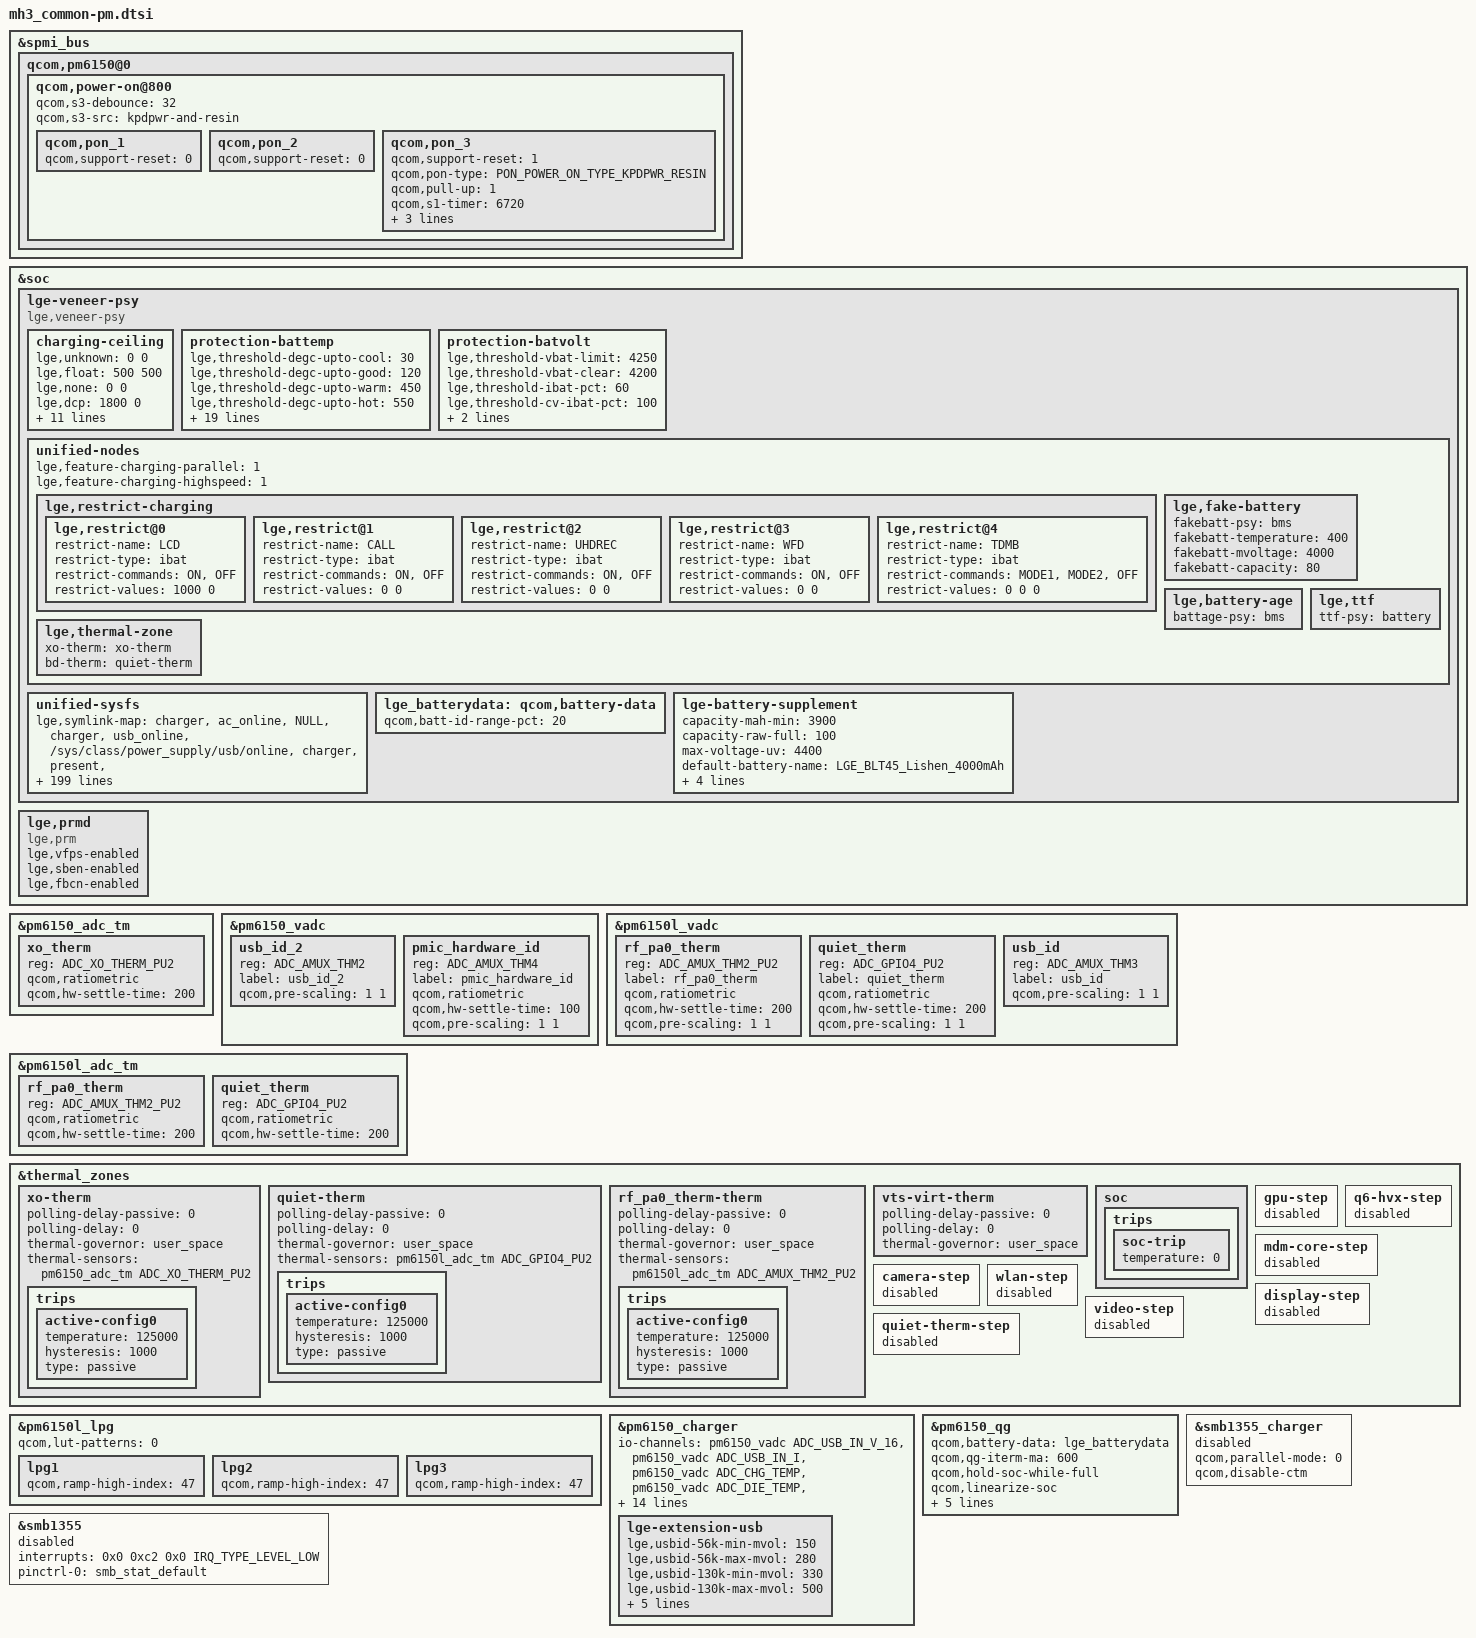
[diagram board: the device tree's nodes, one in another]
/*
 * Copyright (c) 2018, The Linux Foundation. All rights reserved.
 *
 * This program is free software; you can redistribute it and/or modify
 * it under the terms of the GNU General Public License version 2 and
 * only version 2 as published by the Free Software Foundation.
 *
 * This program is distributed in the hope that it will be useful,
 * but WITHOUT ANY WARRANTY; without even the implied warranty of
 * MERCHANTABILITY or FITNESS FOR A PARTICULAR PURPOSE.  See the
 * GNU General Public License for more details.
 */
#include <dt-bindings/input/qcom,qpnp-power-on.h>

&spmi_bus {
       qcom,pm6150@0 {
               qcom,power-on@800 {
                       qcom,s3-debounce = <32>;
                       qcom,s3-src = "kpdpwr-and-resin";

                       qcom,pon_1 {
                               /* KPD_PWR_N */
                               status = "ok";
                               qcom,support-reset = <0>;
                       };

                       qcom,pon_2 {
                               /* RESIN_N */
                               status = "ok";
                               qcom,support-reset = <0>;
                       };

                       qcom,pon_3 {
                               /* KPD_PWR_N AND RESIN_N */
                               status = "ok";
                               qcom,support-reset = <1>;
                               qcom,pon-type = <PON_POWER_ON_TYPE_KPDPWR_RESIN>;
                               qcom,pull-up = <1>;
                               qcom,s1-timer = <6720>;
                               qcom,s2-timer = <2000>;
                               qcom,s2-type = <PON_POWER_OFF_TYPE_DVDD_HARD_RESET>;
                       };
               };
       };
};

&soc {
    lge-veneer-psy {
        compatible = "lge,veneer-psy";
        status = "ok";

        charging-ceiling {
            /*             iusb ibat  : 0 means UNCEILING */
            lge,unknown = <   0    0>;
            lge,float   = < 500  500>;
            lge,none    = <   0    0>;

            lge,dcp     = <1800    0>;
            lge,10k     = <3000    0>;
            lge,22k     = <1500    0>;
            lge,qc2     = <1800    0>;
            lge,qc3     = <1800    0>;

            lge,usb2    = < 500    0>;
            lge,usb3    = < 900    0>;
            lge,cdp     = <1500 1500>;
            lge,pd      = <   0    0>;

            lge,56k     = <1500  500>;
            lge,130k    = <1500  500>;
            lge,910k    = <1500  500>;
        };

        protection-battemp {
            lge,threshold-degc-upto-cool = <30>;
            lge,threshold-degc-upto-good = <120>;
            lge,threshold-degc-upto-warm = <450>;
            lge,threshold-degc-upto-hot = <550>;
            lge,threshold-degc-downto-warm = <520>;
            lge,threshold-degc-downto-good = <430>;
            lge,threshold-degc-downto-cool = <100>;
            lge,threshold-degc-downto-cold = <0>;

            lge,period-ms-emergency = <10000>;
            lge,period-ms-warning   = <30000>;
            lge,period-ms-normal    = <60000>;

            // parameters for warning status cool and warm
            lge,cool-mv-alert   = <4000>;
            lge,cool-ma-alert   = <500>;    // fixed 500 mA
            lge,cool-ma-pct     = <30>;     // means 0.3C rate

            lge,warm-mv-float   = <4000>;
            lge,warm-ma-pct     = <30>;     // means 0.5C rate

            // parameters for battery protection at chilly status
            lge,chilly-status-support;
            lge,chilly-degc-lowerbound = <0>;
            lge,chilly-degc-upperbound = <150>;
            lge,chilly-mv-alert    = <4000>;
            lge,chilly-mv-bound     = <200>;
            lge,chilly-ma-alert    = <630>;
            lge,chilly-ma-pct      = <50>;  // means 0.5C rate under batvol 4V
        };

        protection-batvolt {
            lge,threshold-vbat-limit = <4250>;
            lge,threshold-vbat-clear = <4200>;
	    lge,threshold-ibat-pct = <60>;	// means 0.6C rate
	    lge,threshold-cv-ibat-pct = <100>;	// means 0.1C rate

            lge,step-ibat-ma = <100>;
            lge,step-poll-ms = <5000>;
        };

        unified-nodes {
            lge,feature-charging-parallel = <1>;
            lge,feature-charging-highspeed = <1>;

            lge,restrict-charging {
                // restrict-values 0 means UNCEILING

                lge,restrict@0 {
                    restrict-name = "LCD";
                    restrict-type = "ibat";
                    restrict-commands = "ON", "OFF";
                    restrict-values = <1000      0>;
                };
                lge,restrict@1 {
                    restrict-name = "CALL";
                    restrict-type = "ibat";
                    restrict-commands = "ON", "OFF";
                    restrict-values = < 0      0>;
                };
                lge,restrict@2 {
                    restrict-name = "UHDREC";
                    restrict-type = "ibat";
                    restrict-commands = "ON", "OFF";
                    restrict-values = < 0      0>;
                };
                lge,restrict@3 {
                    restrict-name = "WFD";
                    restrict-type = "ibat";
                    restrict-commands = "ON", "OFF";
                    restrict-values = < 0      0>;
                };
                lge,restrict@4 {
                    restrict-name = "TDMB";
                    restrict-type = "ibat";
                    restrict-commands = "MODE1", "MODE2", "OFF";
                    restrict-values = <    0      0      0>;
                };
            };

            lge,fake-battery {
                fakebatt-psy = "bms";       // What 'psy' does implement(or support) the fake battery?
                fakebatt-temperature = <400>;
                fakebatt-mvoltage = <4000>;
                fakebatt-capacity = <80>;
            };

            lge,battery-age {
                battage-psy = "bms";        // What 'psy' does implement(or support) the battery age?
            };

	    lge,thermal-zone {
	    	xo-therm = "xo-therm";
		bd-therm = "quiet-therm";
	    };

            lge,ttf {
                ttf-psy = "battery";	// What 'psy' does implement(or support) the time to full now?
            };
        };

        unified-sysfs {
            lge,symlink-map =
                /* group , user_node, kernel node */
                /* Charger */
                "charger",                     "ac_online", "NULL",
                "charger",                    "usb_online", "/sys/class/power_supply/usb/online",   /* TODO */
                "charger",                       "present", "/sys/class/power_supply/usb/present",
                "charger",                    "wlc_online", "/sys/class/power_supply/wireless/online",
                "charger",                          "type", "/sys/class/power_supply/usb/real_type",
		"charger",                   "usb_pd_type", "/sys/class/power_supply/usb/real_type",
                "charger",                      "time_out", "/sys/class/power_supply/battery/safety_timer_enabled",
                "charger",              "charging_enabled", "/sys/devices/platform/lge-unified-nodes/charging_enable",
                "charger",                  "ibat_current", "/sys/class/power_supply/battery/current_now",
                "charger",                  "ichg_current", "/sys/class/power_supply/usb/current_max",
                "charger",                  "iusb_control", "NULL",
                "charger",            "thermal_mitigation", "NULL",
                "charger",        "wlc_thermal_mitigation", "NULL",
                "charger",       "usb_parallel_chg_status", "NULL",
                "charger", "usb_parallel_charging_enabled", "/sys/class/power_supply/parallel/charging_enabled",
                "charger", "factory_parallel_charger_test", "/sys/devices/platform/lge-unified-nodes/support_fastpl",
                "charger",            "moisture_detection", "/sys/class/power_supply/usb/moisture_detected",
                "charger",           "restricted_charging", "/sys/devices/platform/lge-unified-nodes/charging_restriction",
                "charger",              "ibat_max_current", "/sys/class/power_supply/battery/constant_charge_current_max",
                "charger",                       "chgstep", "/sys/devices/platform/lge-unified-nodes/charging_step",
                "charger",               "connection_type", "NULL",
                "charger",                       "fastchg", "/sys/devices/platform/lge-unified-nodes/charger_highspeed",
                "charger",         "input_current_settled", "/sys/class/power_supply/usb/input_current_settled",
                "charger",             "input_current_max", "/sys/class/power_supply/usb/input_current_settled",
                "charger",            "store_demo_enabled", "NULL",
                "charger",     "wireless_charging_enabled", "NULL",
                "charger",                 "input_suspend", "/sys/class/power_supply/battery/input_suspend",
                "charger",                  "incompatible", "/sys/devices/platform/lge-unified-nodes/charger_incompatible",
                "charger",                    "hvdcp_fake", "/sys/devices/platform/lge-unified-nodes/fake_hvdcp",
                "charger",               "usb_current_max", "/sys/devices/platform/lge-unified-nodes/fake_sdpmax",
                "charger",               "fastchg_support", "/sys/devices/platform/lge-unified-nodes/support_fastchg",
                "charger",                    "usbid_type", "/sys/class/power_supply/usb/resistance_id",
                "charger",                 "ccd_batchg_en", "/sys/devices/platform/lge-unified-nodes/ccd_batchg_en",
                "charger",             "ccd_input_suspend", "/sys/devices/platform/lge-unified-nodes/ccd_input_suspend",
                "charger",                       "ccd_icl", "/sys/devices/platform/lge-unified-nodes/ccd_icl",
                "charger",                       "ccd_fcc", "/sys/devices/platform/lge-unified-nodes/ccd_fcc",
                "charger",                    "ccd_vfloat", "/sys/devices/platform/lge-unified-nodes/ccd_vfloat",
		"charger",                     "aicl_done", "/sys/devices/platform/lge-unified-nodes/aicl_done",
                /* ADC/MPP */
                "adc",              "thermal", "/sys/class/thermal/",
		"adc",             "xo_therm", "/sys/bus/iio/devices/iio:device0/in_temp_xo_therm_input",
                "adc",           "batt_therm", "/sys/class/power_supply/battery/temp",
                "adc",              "batt_id", "/sys/devices/platform/lge-unified-nodes/battery_valid",
		"adc",            "pa_therm0", "/sys/bus/iio/devices/iio:device1/in_temp_rf_pa0_therm_input",
		"adc",            "pa_therm1", "NULL",
		"adc",           "quiet_therm","/sys/bus/iio/devices/iio:device1/in_temp_quiet_therm_input",
                "adc",               "usb_in", "/sys/class/power_supply/usb/voltage_now",
		"adc",                "vcoin", "/sys/bus/iio/devices/iio:device0/in_voltage_vcoin_input",
		"adc",              "vph_pwr", "/sys/bus/iio/devices/iio:device0/in_voltage_vph_pwr_input",
                "adc",               "usb_id", "/sys/devices/platform/lge-unified-nodes/charger_usbid",
                "adc",             "usb_edge", "NULL",
                "adc",                 "pmic", "/sys/class/thermal/thermal_zone0/temp",
                "adc",                  "vts", "/sys/bus/platform/drivers/monitor-thermal/soc:lge,monitor-thermal/vts_temp",
                /* Battery */
                "battery",         "capacity", "/sys/class/power_supply/battery/capacity",
                "battery",           "health", "/sys/class/power_supply/battery/health",
                "battery",          "present", "/sys/class/power_supply/battery/present",
                "battery",      "pseudo_batt", "/sys/devices/platform/lge-unified-nodes/fake_battery",
                "battery",           "status", "/sys/class/power_supply/battery/status",
                "battery",       "status_raw", "NULL",
                "battery",             "temp", "/sys/class/power_supply/battery/temp",
                "battery",    "valid_batt_id", "/sys/devices/platform/lge-unified-nodes/battery_valid",
                "battery",      "voltage_now", "/sys/class/power_supply/battery/voltage_now",
                "battery",          "vzw_chg", "/sys/devices/platform/lge-unified-nodes/charger_verbose",
		"battery",     "raw_capacity", "/sys/class/power_supply/bms/capacity_raw",
                "battery",        "condition", "/sys/devices/platform/lge-unified-nodes/battery_condition",
                "battery",      "battery_age", "/sys/devices/platform/lge-unified-nodes/battery_age",
                "battery","battery_age_level", "/sys/devices/platform/lge-unified-nodes/battery_age",
                "battery",            "cycle", "/sys/class/power_supply/bms/cycle_count",
                "battery",     "battery_type", "/sys/class/power_supply/bms/battery_type",
                "battery",      "charge_full", "/sys/class/power_supply/bms/charge_full",
                "battery",   "charge_now_raw", "/sys/class/power_supply/bms/charge_now_raw",
                "battery",     "ttf_capacity", "/sys/devices/platform/lge-unified-nodes/ttf_capacity",
                "battery", "time_to_full_now", "/sys/devices/platform/lge-unified-nodes/time_to_full_now",
                /* LCD Backlight */
                "lcd",           "brightness", "/sys/class/backlight/panel0-backlight/brightness",
                "lcd",       "max_brightness", "/sys/class/backlight/panel0-backlight/max_brightness",
                "lcd_ex",        "brightness", "NULL",
                "lcd_ex",    "max_brightness", "NULL",
                /* KEY LED */
                "key_led",   "red_brightness", "/sys/class/leds/red/brightness",
                "key_led", "green_brightness", "/sys/class/leds/green/brightness",
                "key_led",  "blue_brightness", "/sys/class/leds/blue/brightness",
                "key_led",  "setting",         "/sys/class/lg_rgb_led/use_patterns/setting",
                /* CPU */
                "cpu",       "cpu_idle_modes", "NULL",
                /* GPU */
                "gpu",                 "busy", "/sys/class/kgsl/kgsl-3d0/gpubusy",
                "gpu",               "gpuclk", "/sys/class/kgsl/kgsl-3d0/gpuclk",
                /* PLATFORM */
                "platform",       "speed_bin", "NULL",
                "platform",         "pvs_bin", "NULL",
                "platform",     "power_state", "/sys/power/autosleep",
                "platform",   "poweron_alarm", "/sys/module/qpnp_rtc/parameters/poweron_alarm",
		"platform",         "pcb_rev", "/sys/bus/iio/devices/iio:device0/in_voltage_pmic_hardware_id_input",
                "platform",       "smpl_boot", "/sys/module/lge_smpl_count/parameters/smpl_boot",
                /* testmode */
                "testmode",            "temp", "/sys/class/power_supply/battery/temp",
                "testmode",     "voltage_now", "/sys/class/power_supply/battery/voltage_now",
                "testmode",          "usb_id", "/sys/devices/platform/lge-unified-nodes/charger_usbid",
                "testmode",         "batt_id", "/sys/devices/platform/lge-unified-nodes/battery_valid",
                "testmode",         "fuelval", "/sys/class/power_supply/battery/capacity",
		"testmode",        "xo_therm", "/sys/devices/platform/lge-unified-nodes/factory_xo_therm",
                "testmode",          "charge", "/sys/class/power_supply/battery/battery_charging_enabled",
                "testmode",          "chcomp", "/sys/devices/platform/lge-unified-nodes/charging_completed",
                "testmode",           "usbin", "/sys/class/power_supply/usb/voltage_now",
		"testmode",       "pa_therm0", "/sys/bus/iio/devices/iio:device1/in_temp_rf_pa0_therm_input",
		"testmode",       "pa_therm1", "NULL",
		"testmode",       "bd_therm2", "/sys/devices/platform/lge-unified-nodes/factory_bd_therm",
		"testmode",           "vcoin", "/sys/bus/iio/devices/iio:device0/in_voltage_vcoin_input",
		"testmode",         "vph_pwr", "/sys/bus/iio/devices/iio:device0/in_voltage_vph_pwr_input",
                "testmode",     "current_now", "/sys/class/power_supply/battery/current_now",
                "testmode",     "current_max", "/sys/class/power_supply/usb/current_max",
		"testmode",         "pcb_rev", "/sys/bus/iio/devices/iio:device0/in_voltage_pmic_hardware_id_input",
                "testmode",      "chgmodeoff", "/sys/class/power_supply/battery/input_suspend",
                "testmode",         "fuelrst", "/sys/class/power_supply/battery/present",
                "testmode",        "rtc_time", "/dev/rtc0",
                "testmode",           "pmrst", "NULL",
                "testmode",        "battexit", "/sys/class/power_supply/battery/present",
                "testmode",  "hardreset_mode", "NULL",
                /* ps feature*/
                "psfeature",     "vfps_ratio", "/sys/class/power/vfps/vfps_ratio",
                "psfeature",           "vfps", "/sys/class/power/vfps/vfps",
                "psfeature",      "vfps_fcnt", "/sys/class/power/vfps/vfps_fcnt",
                "psfeature",  "triton_policy", "NULL",
                "psfeature",   "cancun_is_cm", "NULL",
                "regulator",       "vreg_bob", "NULL";
        };

	lge_batterydata: qcom,battery-data {
		qcom,batt-id-range-pct = <20>;
		#include "../battery_profile/LGE_BLT45_Lishen_4000mAh.dtsi"
		#include "../battery_profile/LGE_BLT45_Tocad_4000mAh.dtsi"
	};

	lge-battery-supplement {
	   capacity-mah-min = <3900>;
	   capacity-raw-full = <100>;
	   max-voltage-uv = <4400>;

	   default-battery-name = "LGE_BLT45_Lishen_4000mAh";
	   default-battery-kohm = <200>;

	/* format : (temp index) (temp delta) */
	   tempcomp-offset = <
	        (-300)    0
	        (-200)    0
	        (-190)    0
	        (-180)    0
	        (-170)    0
	        (-160)    0
	        (-150)    0
	        (-100)    0
	        ( -50)    0
	        0         0
	        50        0
	        100       0
	        150       0
	        200       0
	        250     0
	        300     0
	        350     0
	        400     0
	        450     0
	        500     0
	        550     0
	        600     0
	        700     0
	        800     0
	        900     0
	        >;
	   tempcomp-icoeff = <0>;

	/* overriding by battery type */
	/*
		LGE_BLT45_Lishen_4000mAh {
	        tempcomp-icoeff = <0>;
	        };
		LGE_BLT45_Tocad_4000mAh {
	        tempcomp-icoeff = <0>;
	        };
	*/
	};
    };
};


&soc {
	lge,prmd {
		compatible = "lge,prm";
		lge,vfps-enabled;
		lge,sben-enabled;
		lge,fbcn-enabled;
	};
};

&pm6150_adc_tm {
	xo_therm {
		reg = <ADC_XO_THERM_PU2>;
		qcom,ratiometric;
		qcom,hw-settle-time = <200>;
	};
};

&pm6150_vadc {
	usb_id_2 {
		reg = <ADC_AMUX_THM2>;
		label = "usb_id_2";
		qcom,pre-scaling = <1 1>;
	};

        pmic_hardware_id {
                reg = <ADC_AMUX_THM4>;
                label = "pmic_hardware_id";
                qcom,ratiometric;
                qcom,hw-settle-time = <100>;
                qcom,pre-scaling = <1 1>;
        };
};

&pm6150l_vadc {
	rf_pa0_therm {
		reg = <ADC_AMUX_THM2_PU2>;
		label = "rf_pa0_therm";
		qcom,ratiometric;
		qcom,hw-settle-time = <200>;
		qcom,pre-scaling = <1 1>;
	};

	quiet_therm {
		reg = <ADC_GPIO4_PU2>;
		label = "quiet_therm";
		qcom,ratiometric;
		qcom,hw-settle-time = <200>;
		qcom,pre-scaling = <1 1>;
	};

        usb_id {
                reg = <ADC_AMUX_THM3>;
                label = "usb_id";
                qcom,pre-scaling = <1 1>;
        };

};

&pm6150l_adc_tm {
	rf_pa0_therm {
		reg = <ADC_AMUX_THM2_PU2>;
		qcom,ratiometric;
		qcom,hw-settle-time = <200>;
	};

	quiet_therm {
		reg = <ADC_GPIO4_PU2>;
		qcom,ratiometric;
		qcom,hw-settle-time = <200>;
	};
};

&thermal_zones {
	xo-therm {
		polling-delay-passive = <0>;
		polling-delay = <0>;
		thermal-governor = "user_space";
		thermal-sensors = <&pm6150_adc_tm ADC_XO_THERM_PU2>;
		trips {
			active-config0 {
				temperature = <125000>;
				hysteresis = <1000>;
				type = "passive";
			};
		};
	};

	quiet-therm {
		polling-delay-passive = <0>;
		polling-delay = <0>;
		thermal-governor = "user_space";
		thermal-sensors = <&pm6150l_adc_tm ADC_GPIO4_PU2>;
		trips {
			active-config0 {
				temperature = <125000>;
				hysteresis = <1000>;
				type = "passive";
			};
		};
	};

	rf_pa0_therm-therm {
		polling-delay-passive = <0>;
		polling-delay = <0>;
		thermal-governor = "user_space";
		thermal-sensors = <&pm6150l_adc_tm ADC_AMUX_THM2_PU2>;
		trips {
			active-config0 {
				temperature = <125000>;
				hysteresis = <1000>;
				type = "passive";
			};
		};
	};

	vts-virt-therm {
		polling-delay-passive = <0>;
		polling-delay = <0>;
		thermal-governor = "user_space";
	};

	soc {
		trips {
			soc-trip {
				temperature = <0>;
			};
		};
	};

	gpu-step {
		status = "disabled";
	};

	q6-hvx-step {
		status = "disabled";
	};

	mdm-core-step {
		status = "disabled";
	};

	camera-step {
		status = "disabled";
	};

	wlan-step {
		status = "disabled";
	};

	display-step {
		status = "disabled";
	};

	video-step {
		status = "disabled";
	};

	quiet-therm-step {
		status = "disabled";
	};
};

&pm6150l_lpg {
        qcom,lut-patterns = <0>;

        lpg1 {
            qcom,ramp-high-index = <47>;
        };

        lpg2 {
            qcom,ramp-high-index = <47>;
        };

        lpg3 {
            qcom,ramp-high-index = <47>;
        };
};

&pm6150_charger {
    io-channels = <&pm6150_vadc ADC_USB_IN_V_16>,
		      <&pm6150_vadc ADC_USB_IN_I>,
		      <&pm6150_vadc ADC_CHG_TEMP>,
		      <&pm6150_vadc ADC_DIE_TEMP>,
		      <&pm6150_vadc ADC_AMUX_THM4_PU2>,
		      <&pm6150_vadc ADC_SBUx>,
		      <&pm6150_vadc ADC_VPH_PWR>,
		      <&pm6150l_vadc ADC_AMUX_THM3>;
    io-channel-names = "usb_in_voltage",
			   "usb_in_current",
			   "chg_temp",
			   "die_temp",
			   "conn_temp",
			   "sbux_res",
			   "vph_voltage",
			   "usb_id";
    qcom,battery-data = <&lge_batterydata>;
    qcom,auto-recharge-soc = <98>;
    qcom,fcc-max-ua = <2800000>;
    qcom,usb-icl-ua = <1800000>;
    qcom,fv-max-uv = <4400000>;
    qcom,chg-term-src = <1>;
    qcom,chg-term-current-ma = <(-170)>;
    lge,parallel-pct = <0>;
    qcom,suspend-input-on-debug-batt;
    qcom,sec-charger-config = <0>;

    lge-extension-usb {
        lge,usbid-56k-min-mvol = <150>;
		lge,usbid-56k-max-mvol = <280>;
		lge,usbid-130k-min-mvol = <330>;
		lge,usbid-130k-max-mvol = <500>;
		lge,usbid-910k-min-mvol = <750>;
		lge,usbid-910k-max-mvol = <900>;
		lge,usbid-open-min-mvol = <950>;
		lge,usbid-open-max-mvol = <1100>;

        lge,feature-moisture-charging = <0>;
    };
};

&pm6150_qg {
    qcom,battery-data = <&lge_batterydata>;
    qcom,qg-iterm-ma = <600>;
    qcom,hold-soc-while-full;
    qcom,linearize-soc;
    qcom,cl-feedback-on;
	qcom,cl-min-start-soc = <0>;
	qcom,s3-entry-ibat-ua = <18000>;
	qcom,esr-discharge-enable;
	qcom,s3-exit-ibat-ua = <38000>; //exit point is default 20mA higher

};

&smb1355 {
        /delete-property/ interrupts;
        interrupts = <0x0 0xc2 0x0 IRQ_TYPE_LEVEL_LOW>;
		pinctrl-names = "default";
		pinctrl-0 = <&smb_stat_default>;
        status = "disabled";
};

&smb1355_charger {
        status = "disabled";
        qcom,parallel-mode = <0>;
        qcom,disable-ctm;
};
